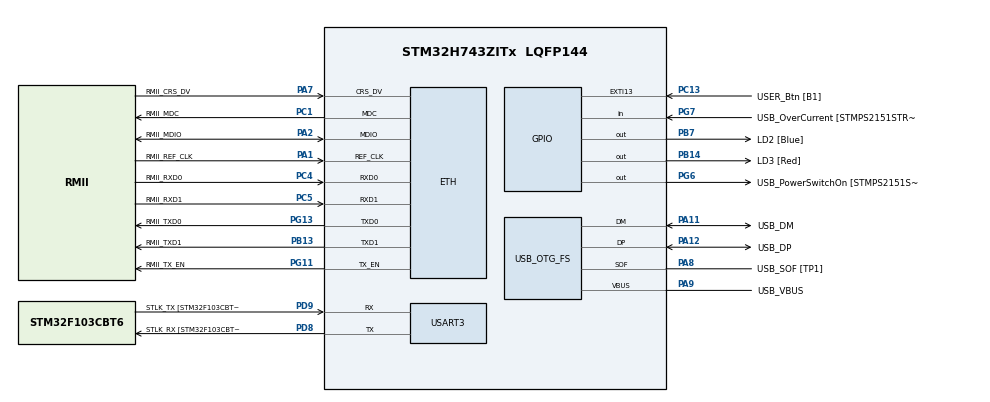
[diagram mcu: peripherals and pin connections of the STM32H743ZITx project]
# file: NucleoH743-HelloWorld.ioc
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ARM.CMSIS.4.5.0.CMSISJjCORE=true
ARM.CMSIS.4.5.0.CMSISJjDSP=true
ETH.MediaInterface=HAL_ETH_RMII_MODE
FREERTOS.Tasks01=defaultTask,24,4096,StartDefaultTask,Default,NULL,Static,defaultTaskBuffer,defaultTaskControlBlock;myTask02,24,256,StartTask02,Default,NULL,Dynamic,NULL,NULL
FREERTOS.configTOTAL_HEAP_SIZE=15360
Mcu.Family=STM32H7
Mcu.Name=STM32H743ZITx
Mcu.Package=LQFP144
NVIC.OTG_FS_IRQn=true\:5\:0\:false\:false\:true\:true\:false\:true
NVIC.PriorityGroup=NVIC_PRIORITYGROUP_4
NVIC.TIM17_IRQn=true\:0\:0\:false\:false\:true\:false\:false\:true
NVIC.TimeBase=TIM17_IRQn
NVIC.TimeBaseIP=TIM17
PA1.GPIO_Label=RMII_REF_CLK
PA1.Mode=RMII
PA1.Signal=ETH_REF_CLK
PA10.GPIO_Label=USB_ID
PA10.Signal=USB_OTG_FS_ID
PA11.GPIO_Label=USB_DM
PA11.Mode=Device_Only
PA11.Signal=USB_OTG_FS_DM
PA12.GPIO_Label=USB_DP
PA12.Mode=Device_Only
PA12.Signal=USB_OTG_FS_DP
PA2.GPIO_Label=RMII_MDIO
PA2.Mode=RMII
PA2.Signal=ETH_MDIO
PA7.GPIO_Label=RMII_CRS_DV
PA7.Mode=RMII
PA7.Signal=ETH_CRS_DV
PA8.GPIO_Label=USB_SOF [TP1]
PA8.Mode=Activate_SOF_FS
PA8.Signal=USB_OTG_FS_SOF
PA9.GPIO_Label=USB_VBUS
PA9.Mode=Activate_VBUS
PA9.Signal=USB_OTG_FS_VBUS
PB13.GPIO_Label=RMII_TXD1
PB13.Mode=RMII
PB13.Signal=ETH_TXD1
PB14.GPIO_Label=LD3 [Red]
PB14.Signal=GPIO_Output
PB7.GPIO_Label=LD2 [Blue]
PB7.Signal=GPIO_Output
PC1.GPIO_Label=RMII_MDC
PC1.Mode=RMII
PC1.Signal=ETH_MDC
PC13.GPIO_Label=USER_Btn [B1]
PC13.Signal=GPXTI13
PC14-OSC32_IN\ (OSC32_IN).Mode=LSE-External-Oscillator
PC14-OSC32_IN\ (OSC32_IN).Signal=RCC_OSC32_IN
PC15-OSC32_OUT\ (OSC32_OUT).Mode=LSE-External-Oscillator
PC15-OSC32_OUT\ (OSC32_OUT).Signal=RCC_OSC32_OUT
PC4.GPIO_Label=RMII_RXD0
PC4.Mode=RMII
PC4.Signal=ETH_RXD0
PC5.GPIO_Label=RMII_RXD1
PC5.Mode=RMII
PC5.Signal=ETH_RXD1
PD8.GPIO_Label=STLK_RX [STM32F103CBT6_PA3]
PD8.Mode=Asynchronous
PD8.Signal=USART3_TX
PD9.GPIO_Label=STLK_TX [STM32F103CBT6_PA2]
PD9.Mode=Asynchronous
PD9.Signal=USART3_RX
PG11.GPIO_Label=RMII_TX_EN
PG11.Mode=RMII
PG11.Signal=ETH_TX_EN
PG13.GPIO_Label=RMII_TXD0
PG13.Mode=RMII
PG13.Signal=ETH_TXD0
PG6.GPIO_Label=USB_PowerSwitchOn [STMPS2151STR_EN]
PG6.Signal=GPIO_Output
PG7.GPIO_Label=USB_OverCurrent [STMPS2151STR_FAULT]
PG7.Signal=GPIO_Input
PH0-OSC_IN\ (PH0).GPIO_Label=MCO
PH0-OSC_IN\ (PH0).Mode=HSE-External-Clock-Source
PH0-OSC_IN\ (PH0).Signal=RCC_OSC_IN
PH1-OSC_OUT\ (PH1).Signal=RCC_OSC_OUT
ProjectManager.HeapSize=0x200
ProjectManager.StackSize=0x400
ProjectManager.TargetToolchain=STM32CubeIDE
RCC.48MHZClocksFreq_Value=24000000
RCC.ADCFreq_Value=16125000
RCC.AHBFreq_Value=216000000
RCC.APB1CLKDivider=RCC_HCLK_DIV4
RCC.APB1Freq_Value=120000000
RCC.APB1TimFreq_Value=108000000
RCC.APB2CLKDivider=RCC_HCLK_DIV2
RCC.APB2Freq_Value=120000000
RCC.APB2TimFreq_Value=216000000
RCC.APB3Freq_Value=120000000
RCC.APB4Freq_Value=120000000
RCC.CortexFreq_Value=480000000
RCC.D1PPRE=RCC_APB3_DIV2
RCC.D2PPRE1=RCC_APB1_DIV2
RCC.D2PPRE2=RCC_APB2_DIV2
RCC.D3PPRE=RCC_APB4_DIV2
RCC.DIVM1=1
RCC.DIVM3=1
RCC.DIVN1=120
RCC.DIVN3=24
RCC.DIVQ1=10
RCC.DIVQ3=4
RCC.FLatency=FLASH_LATENCY_4
RCC.HCLKFreq_Value=240000000
RCC.HPRE=RCC_HCLK_DIV2
RCC.HSE_VALUE=8000000
RCC.HSI_VALUE=64000000
RCC.PLL2FRACN=0
RCC.PLL3FRACN=0
RCC.PLLFRACN=0
RCC.PLLM=25
RCC.PLLMUL=RCC_PLL_MUL9
RCC.PLLN=432
RCC.PLLQ=9
RCC.PLLSourceVirtual=RCC_PLLSOURCE_HSE
RCC.PRESCALERUSB=RCC_USBCLKSOURCE_PLL_DIV1_5
RCC.SYSCLKFreq_VALUE=480000000
RCC.SYSCLKSource=RCC_SYSCLKSOURCE_PLLCLK
RCC.SYSCLKSourceVirtual=RCC_SYSCLKSOURCE_PLLCLK
RCC.USBCLockSelection=RCC_USBCLKSOURCE_PLL3
RCC.USBFreq_Value=48000000
RCC.VCOOutputFreq_Value=432000000
USART3.VirtualMode-Asynchronous=VM_ASYNC
USB_DEVICE.CLASS_NAME_FS=CDC
USB_DEVICE.VirtualMode-CDC_FS=Cdc
USB_DEVICE.VirtualModeFS=Cdc_FS
USB_OTG_FS.VirtualMode=Device_Only
VP_ARM.CMSIS_VS_CMSISJjCORE_4.3.0_4.5.0.Mode=CMSISJjCORE
VP_ARM.CMSIS_VS_CMSISJjDSP_1.4.6_4.5.0.Mode=CMSISJjDSP
VP_FREERTOS_VS_CMSIS_V2.Mode=CMSIS_V2
VP_SYS_VS_tim17.Mode=TIM17
VP_USB_DEVICE_VS_USB_DEVICE_CDC_FS.Mode=CDC_FS
board=NUCLEO-H743ZI

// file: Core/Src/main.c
/* USER CODE BEGIN Header */
/**
  ******************************************************************************
  * @file           : main.c
  * @brief          : Main program body
  ******************************************************************************
  * @attention
  *
  * <h2><center>&copy; Copyright (c) 2020 STMicroelectronics.
  * All rights reserved.</center></h2>
  *
  * This software component is licensed by ST under BSD 3-Clause license,
  * the "License"; You may not use this file except in compliance with the
  * License. You may obtain a copy of the License at:
  *                        opensource.org/licenses/BSD-3-Clause
  *
  ******************************************************************************
  */
/* USER CODE END Header */
#include "main.h"
#include "string.h"
#include "cmsis_os.h"
#include "usb_device.h"

typedef StaticTask_t osStaticThreadDef_t;

#if defined ( __ICCARM__ ) /*!< IAR Compiler */

#pragma location=0x30040000
ETH_DMADescTypeDef  DMARxDscrTab[ETH_RX_DESC_CNT]; /* Ethernet Rx DMA Descriptors */
#pragma location=0x30040060
ETH_DMADescTypeDef  DMATxDscrTab[ETH_TX_DESC_CNT]; /* Ethernet Tx DMA Descriptors */
#pragma location=0x30040200
uint8_t Rx_Buff[ETH_RX_DESC_CNT][ETH_MAX_PACKET_SIZE]; /* Ethernet Receive Buffers */

#elif defined ( __CC_ARM )  /* MDK ARM Compiler */

__attribute__((at(0x30040000))) ETH_DMADescTypeDef  DMARxDscrTab[ETH_RX_DESC_CNT]; /* Ethernet Rx DMA Descriptors */
__attribute__((at(0x30040060))) ETH_DMADescTypeDef  DMATxDscrTab[ETH_TX_DESC_CNT]; /* Ethernet Tx DMA Descriptors */
__attribute__((at(0x30040200))) uint8_t Rx_Buff[ETH_RX_DESC_CNT][ETH_MAX_PACKET_SIZE]; /* Ethernet Receive Buffer */

#elif defined ( __GNUC__ ) /* GNU Compiler */

ETH_DMADescTypeDef DMARxDscrTab[ETH_RX_DESC_CNT] __attribute__((section(".RxDecripSection"))); /* Ethernet Rx DMA Descriptors */
ETH_DMADescTypeDef DMATxDscrTab[ETH_TX_DESC_CNT] __attribute__((section(".TxDecripSection")));   /* Ethernet Tx DMA Descriptors */
uint8_t Rx_Buff[ETH_RX_DESC_CNT][ETH_MAX_PACKET_SIZE] __attribute__((section(".RxArraySection"))); /* Ethernet Receive Buffers */

#endif

ETH_TxPacketConfig TxConfig;

ETH_HandleTypeDef heth;

UART_HandleTypeDef huart3;

/* Definitions for defaultTask */
osThreadId_t defaultTaskHandle;
uint32_t defaultTaskBuffer[ 4096 ];
osStaticThreadDef_t defaultTaskControlBlock;
const osThreadAttr_t defaultTask_attributes = {
  .name = "defaultTask",
  .stack_mem = &defaultTaskBuffer[0],
  .stack_size = sizeof(defaultTaskBuffer),
  .cb_mem = &defaultTaskControlBlock,
  .cb_size = sizeof(defaultTaskControlBlock),
  .priority = (osPriority_t) osPriorityNormal,
};
/* Definitions for myTask02 */
osThreadId_t myTask02Handle;
const osThreadAttr_t myTask02_attributes = {
  .name = "myTask02",
  .priority = (osPriority_t) osPriorityNormal,
  .stack_size = 256 * 4
};

void SystemClock_Config(void);
static void MX_GPIO_Init(void);
static void MX_ETH_Init(void);
static void MX_USART3_UART_Init(void);
void StartDefaultTask(void *argument);
void StartTask02(void *argument);

/* USER CODE BEGIN PFP */
extern void setup(void);
extern void loop0(void);
extern void loop1(void);
/* USER CODE END PFP */

int main(void)
{

  /* MCU Configuration--------------------------------------------------------*/

  /* Reset of all peripherals, Initializes the Flash interface and the Systick. */
  HAL_Init();

  /* Configure the system clock */
  SystemClock_Config();

  /* Initialize all configured peripherals */
  MX_GPIO_Init();
  MX_ETH_Init();
  MX_USART3_UART_Init();

  /* Init scheduler */
  osKernelInitialize();

  /* Create the thread(s) */
  /* creation of defaultTask */
  defaultTaskHandle = osThreadNew(StartDefaultTask, NULL, &defaultTask_attributes);

  /* creation of myTask02 */
  myTask02Handle = osThreadNew(StartTask02, NULL, &myTask02_attributes);

  /* Start scheduler */
  osKernelStart();

  /* We should never get here as control is now taken by the scheduler */
  /* Infinite loop */
  while (1)
  {

  }
}

void SystemClock_Config(void)
{
  RCC_OscInitTypeDef RCC_OscInitStruct = {0};
  RCC_ClkInitTypeDef RCC_ClkInitStruct = {0};
  RCC_PeriphCLKInitTypeDef PeriphClkInitStruct = {0};

  /** Supply configuration update enable
  */
  HAL_PWREx_ConfigSupply(PWR_LDO_SUPPLY);
  /** Configure the main internal regulator output voltage
  */
  __HAL_PWR_VOLTAGESCALING_CONFIG(PWR_REGULATOR_VOLTAGE_SCALE0);

  while(!__HAL_PWR_GET_FLAG(PWR_FLAG_VOSRDY)) {}
  /** Macro to configure the PLL clock source
  */
  __HAL_RCC_PLL_PLLSOURCE_CONFIG(RCC_PLLSOURCE_HSE);
  /** Initializes the RCC Oscillators according to the specified parameters
  * in the RCC_OscInitTypeDef structure.
  */
  RCC_OscInitStruct.OscillatorType = RCC_OSCILLATORTYPE_HSE;
  RCC_OscInitStruct.HSEState = RCC_HSE_BYPASS;
  RCC_OscInitStruct.PLL.PLLState = RCC_PLL_ON;
  RCC_OscInitStruct.PLL.PLLSource = RCC_PLLSOURCE_HSE;
  RCC_OscInitStruct.PLL.PLLM = 1;
  RCC_OscInitStruct.PLL.PLLN = 120;
  RCC_OscInitStruct.PLL.PLLP = 2;
  RCC_OscInitStruct.PLL.PLLQ = 10;
  RCC_OscInitStruct.PLL.PLLR = 2;
  RCC_OscInitStruct.PLL.PLLRGE = RCC_PLL1VCIRANGE_3;
  RCC_OscInitStruct.PLL.PLLVCOSEL = RCC_PLL1VCOWIDE;
  RCC_OscInitStruct.PLL.PLLFRACN = 0;
  if (HAL_RCC_OscConfig(&RCC_OscInitStruct) != HAL_OK)
  {
    Error_Handler();
  }
  /** Initializes the CPU, AHB and APB buses clocks
  */
  RCC_ClkInitStruct.ClockType = RCC_CLOCKTYPE_HCLK|RCC_CLOCKTYPE_SYSCLK
                              |RCC_CLOCKTYPE_PCLK1|RCC_CLOCKTYPE_PCLK2
                              |RCC_CLOCKTYPE_D3PCLK1|RCC_CLOCKTYPE_D1PCLK1;
  RCC_ClkInitStruct.SYSCLKSource = RCC_SYSCLKSOURCE_PLLCLK;
  RCC_ClkInitStruct.SYSCLKDivider = RCC_SYSCLK_DIV1;
  RCC_ClkInitStruct.AHBCLKDivider = RCC_HCLK_DIV2;
  RCC_ClkInitStruct.APB3CLKDivider = RCC_APB3_DIV2;
  RCC_ClkInitStruct.APB1CLKDivider = RCC_APB1_DIV2;
  RCC_ClkInitStruct.APB2CLKDivider = RCC_APB2_DIV2;
  RCC_ClkInitStruct.APB4CLKDivider = RCC_APB4_DIV2;

  if (HAL_RCC_ClockConfig(&RCC_ClkInitStruct, FLASH_LATENCY_4) != HAL_OK)
  {
    Error_Handler();
  }
  PeriphClkInitStruct.PeriphClockSelection = RCC_PERIPHCLK_USART3|RCC_PERIPHCLK_USB;
  PeriphClkInitStruct.PLL3.PLL3M = 1;
  PeriphClkInitStruct.PLL3.PLL3N = 24;
  PeriphClkInitStruct.PLL3.PLL3P = 2;
  PeriphClkInitStruct.PLL3.PLL3Q = 4;
  PeriphClkInitStruct.PLL3.PLL3R = 2;
  PeriphClkInitStruct.PLL3.PLL3RGE = RCC_PLL3VCIRANGE_3;
  PeriphClkInitStruct.PLL3.PLL3VCOSEL = RCC_PLL3VCOWIDE;
  PeriphClkInitStruct.PLL3.PLL3FRACN = 0;
  PeriphClkInitStruct.Usart234578ClockSelection = RCC_USART234578CLKSOURCE_D2PCLK1;
  PeriphClkInitStruct.UsbClockSelection = RCC_USBCLKSOURCE_PLL3;
  if (HAL_RCCEx_PeriphCLKConfig(&PeriphClkInitStruct) != HAL_OK)
  {
    Error_Handler();
  }
  /** Enable USB Voltage detector
  */
  HAL_PWREx_EnableUSBVoltageDetector();
}

static void MX_ETH_Init(void)
{

  heth.Instance = ETH;
  heth.Init.MACAddr[0] =   0x00;
  heth.Init.MACAddr[1] =   0x80;
  heth.Init.MACAddr[2] =   0xE1;
  heth.Init.MACAddr[3] =   0x00;
  heth.Init.MACAddr[4] =   0x00;
  heth.Init.MACAddr[5] =   0x00;
  heth.Init.MediaInterface = HAL_ETH_RMII_MODE;
  heth.Init.TxDesc = DMATxDscrTab;
  heth.Init.RxDesc = DMARxDscrTab;
  heth.Init.RxBuffLen = 1524;

  if (HAL_ETH_Init(&heth) != HAL_OK)
  {
    Error_Handler();
  }

  memset(&TxConfig, 0 , sizeof(ETH_TxPacketConfig));
  TxConfig.Attributes = ETH_TX_PACKETS_FEATURES_CSUM | ETH_TX_PACKETS_FEATURES_CRCPAD;
  TxConfig.ChecksumCtrl = ETH_CHECKSUM_IPHDR_PAYLOAD_INSERT_PHDR_CALC;
  TxConfig.CRCPadCtrl = ETH_CRC_PAD_INSERT;

}

static void MX_USART3_UART_Init(void)
{

  huart3.Instance = USART3;
  huart3.Init.BaudRate = 115200;
  huart3.Init.WordLength = UART_WORDLENGTH_8B;
  huart3.Init.StopBits = UART_STOPBITS_1;
  huart3.Init.Parity = UART_PARITY_NONE;
  huart3.Init.Mode = UART_MODE_TX_RX;
  huart3.Init.HwFlowCtl = UART_HWCONTROL_NONE;
  huart3.Init.OverSampling = UART_OVERSAMPLING_16;
  huart3.Init.OneBitSampling = UART_ONE_BIT_SAMPLE_DISABLE;
  huart3.Init.ClockPrescaler = UART_PRESCALER_DIV1;
  huart3.AdvancedInit.AdvFeatureInit = UART_ADVFEATURE_NO_INIT;
  if (HAL_UART_Init(&huart3) != HAL_OK)
  {
    Error_Handler();
  }
  if (HAL_UARTEx_SetTxFifoThreshold(&huart3, UART_TXFIFO_THRESHOLD_1_8) != HAL_OK)
  {
    Error_Handler();
  }
  if (HAL_UARTEx_SetRxFifoThreshold(&huart3, UART_RXFIFO_THRESHOLD_1_8) != HAL_OK)
  {
    Error_Handler();
  }
  if (HAL_UARTEx_DisableFifoMode(&huart3) != HAL_OK)
  {
    Error_Handler();
  }

}

static void MX_GPIO_Init(void)
{
  GPIO_InitTypeDef GPIO_InitStruct = {0};

  /* GPIO Ports Clock Enable */
  __HAL_RCC_GPIOC_CLK_ENABLE();
  __HAL_RCC_GPIOH_CLK_ENABLE();
  __HAL_RCC_GPIOA_CLK_ENABLE();
  __HAL_RCC_GPIOB_CLK_ENABLE();
  __HAL_RCC_GPIOD_CLK_ENABLE();
  __HAL_RCC_GPIOG_CLK_ENABLE();

  /*Configure GPIO pin Output Level */
  HAL_GPIO_WritePin(GPIOB, LD3_Pin|LD2_Pin, GPIO_PIN_RESET);

  /*Configure GPIO pin Output Level */
  HAL_GPIO_WritePin(USB_PowerSwitchOn_GPIO_Port, USB_PowerSwitchOn_Pin, GPIO_PIN_RESET);

  /*Configure GPIO pin : USER_Btn_Pin */
  GPIO_InitStruct.Pin = USER_Btn_Pin;
  GPIO_InitStruct.Mode = GPIO_MODE_IT_RISING;
  GPIO_InitStruct.Pull = GPIO_NOPULL;
  HAL_GPIO_Init(USER_Btn_GPIO_Port, &GPIO_InitStruct);

  /*Configure GPIO pins : LD3_Pin LD2_Pin */
  GPIO_InitStruct.Pin = LD3_Pin|LD2_Pin;
  GPIO_InitStruct.Mode = GPIO_MODE_OUTPUT_PP;
  GPIO_InitStruct.Pull = GPIO_NOPULL;
  GPIO_InitStruct.Speed = GPIO_SPEED_FREQ_LOW;
  HAL_GPIO_Init(GPIOB, &GPIO_InitStruct);

  /*Configure GPIO pin : USB_PowerSwitchOn_Pin */
  GPIO_InitStruct.Pin = USB_PowerSwitchOn_Pin;
  GPIO_InitStruct.Mode = GPIO_MODE_OUTPUT_PP;
  GPIO_InitStruct.Pull = GPIO_NOPULL;
  GPIO_InitStruct.Speed = GPIO_SPEED_FREQ_LOW;
  HAL_GPIO_Init(USB_PowerSwitchOn_GPIO_Port, &GPIO_InitStruct);

  /*Configure GPIO pin : USB_OverCurrent_Pin */
  GPIO_InitStruct.Pin = USB_OverCurrent_Pin;
  GPIO_InitStruct.Mode = GPIO_MODE_INPUT;
  GPIO_InitStruct.Pull = GPIO_NOPULL;
  HAL_GPIO_Init(USB_OverCurrent_GPIO_Port, &GPIO_InitStruct);

}

void StartDefaultTask(void *argument)
{
  /* init code for USB_DEVICE */
  MX_USB_DEVICE_Init();
  /* USER CODE BEGIN 5 */
  setup();
  /* Infinite loop */
  for(;;)
  {
	loop0();
    //osDelay(1);
  }
  /* USER CODE END 5 */
}

void StartTask02(void *argument)
{
  /* USER CODE BEGIN StartTask02 */

  /* Infinite loop */
  for(;;)
  {
	loop1();
    //osDelay(1);
  }
  /* USER CODE END StartTask02 */
}

 /**
  * @brief  Period elapsed callback in non blocking mode
  * @note   This function is called  when TIM17 interrupt took place, inside
  * HAL_TIM_IRQHandler(). It makes a direct call to HAL_IncTick() to increment
  * a global variable "uwTick" used as application time base.
  * @param  htim : TIM handle
  * @retval None
  */
void HAL_TIM_PeriodElapsedCallback(TIM_HandleTypeDef *htim)
{
  if (htim->Instance == TIM17) {
    HAL_IncTick();
  }
}

void Error_Handler(void)
{
}

/************************ (C) COPYRIGHT STMicroelectronics *****END OF FILE****/
